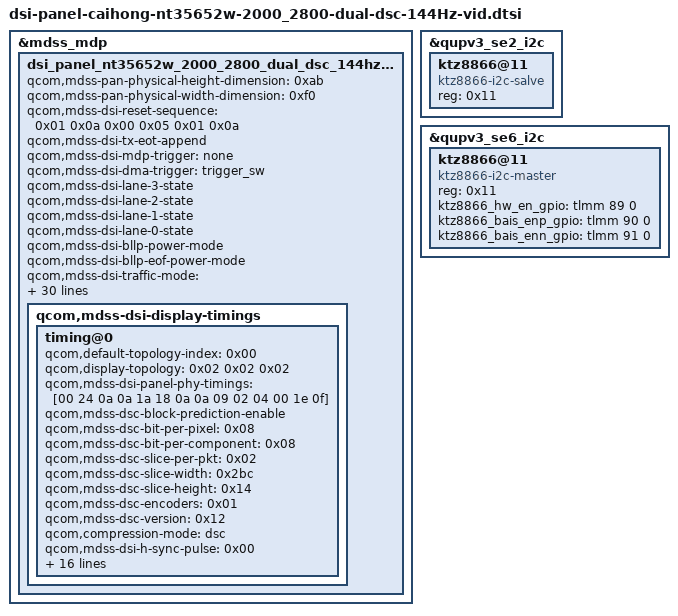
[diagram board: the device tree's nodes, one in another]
&mdss_mdp {
	dsi_panel_nt35652w_2000_2800_dual_dsc_144hz_vid: qcom,mdss_dsi_panel_nt35652w_2000_2800_dual_dsc_144hz_vid {
		qcom,mdss-pan-physical-height-dimension = <0xab>;
		qcom,mdss-pan-physical-width-dimension = <0xf0>;
		qcom,mdss-dsi-reset-sequence = <0x01 0x0a 0x00 0x05 0x01 0x0a>;
		qcom,mdss-dsi-tx-eot-append;
		qcom,mdss-dsi-mdp-trigger = "none";
		qcom,mdss-dsi-dma-trigger = "trigger_sw";
		qcom,mdss-dsi-lane-3-state;
		qcom,mdss-dsi-lane-2-state;
		qcom,mdss-dsi-lane-1-state;
		qcom,mdss-dsi-lane-0-state;
		qcom,mdss-dsi-bllp-power-mode;
		qcom,mdss-dsi-bllp-eof-power-mode;
		qcom,mdss-dsi-traffic-mode = "non_burst_sync_event";
		qcom,mdss-dsi-border-color = <0x00>;
		qcom,mdss-dsi-bpp = <0x18>;
		qcom,mdss-dsi-stream = <0x00>;
		qcom,mdss-dsi-virtual-channel-id = <0x00>;
		oplus,mdss-dsi-manufacture = "novatek";
		oplus,mdss-dsi-vendor-name = "NT36523W";
		qcom,mdss-dsi-panel-type = "dsi_video_mode";
		qcom,mdss-dsi-panel-name = "Dual dsi nt36523w video mode panel with DSC";
	};
};

&dsi_panel_nt35652w_2000_2800_dual_dsc_144hz_vid {
	qcom,panel-supply-entries = <&oplus_dsi_panel_custom_pwr_supply>;
	qcom,dsi-ctrl-num = <0 1>;
	qcom,dsi-phy-num = <0 1>;
	qcom,dsi-select-clocks = "pll_byte_clk0", "pll_dsi_clk0";
	qcom,mdss-dsi-bl-pmic-control-type = "bl_ctrl_external";
	qcom,mdss-dsi-bl-min-level = <10>;
	qcom,mdss-dsi-bl-max-level = <2047>;
	qcom,mdss-brightness-max-level = <2047>;
	qcom,mdss-dsi-bl-inverted-dbv;
	qcom,platform-reset-gpio = <&tlmm 133 0>;
	qcom,esd-check-enabled;
	qcom,mdss-dsi-panel-status-check-mode = "error_flag";
	qcom,error-flag-gpio = <&tlmm 86 0>;
	qcom,error-flag-gpio-slave = <&tlmm 43 0>;
	oplus,bl-use-ktz8866-ic-ctrl;
	oplus,dp-enabled;

	qcom,mdss-dsi-display-timings {
		timing@0 {
			qcom,default-topology-index = <0x00>;
			qcom,display-topology = <0x02 0x02 0x02>;
			qcom,mdss-dsi-panel-phy-timings = [00 24 0a 0a 1a 18 0a 0a 09 02 04 00 1e 0f];
			qcom,mdss-dsc-block-prediction-enable;
			qcom,mdss-dsc-bit-per-pixel = <0x08>;
			qcom,mdss-dsc-bit-per-component = <0x08>;
			qcom,mdss-dsc-slice-per-pkt = <0x02>;
			qcom,mdss-dsc-slice-width = <0x2bc>;
			qcom,mdss-dsc-slice-height = <0x14>;
			qcom,mdss-dsc-encoders = <0x01>;
			qcom,mdss-dsc-version = <0x12>;
			qcom,compression-mode = "dsc";
			qcom,mdss-dsi-h-sync-pulse = <0x00>;
			qcom,mdss-dsi-off-command-state = "dsi_lp_mode";
			qcom,mdss-dsi-on-command-state = "dsi_lp_mode";
			qcom,mdss-dsi-off-command = [05 01 00 00 0a 00 02 28 00 05 01 00 00 41 00 02 10 00];
			qcom,mdss-dsi-on-command = [15 01 00 00 00 00 02 ff 20 15 01 00 00 00 00 02 fb 01 15 01 00 00 00 00 02 62 36 15 01 00 00 00 00 02 63 a4 15 01 00 00 00 00 02 7c 22 15 01 00 00 00 00 02 ff 23 15 01 00 00 00 00 02 fb 01 15 01 00 00 00 00 02 00 60 15 01 00 00 00 00 02 07 20 15 01 00 00 00 00 02 08 01 15 01 00 00 00 00 02 09 5a 15 01 00 00 00 00 02 10 0c 15 01 00 00 00 00 02 11 03 15 01 00 00 00 00 02 12 6b 15 01 00 00 00 00 02 15 03 15 01 00 00 00 00 02 16 10 15 01 00 00 00 00 02 0a 8e 15 01 00 00 00 00 02 0b 8e 15 01 00 00 00 00 02 0c 8e 15 01 00 00 00 00 02 0d 00 15 01 00 00 00 00 02 19 00 15 01 00 00 00 00 02 1a 04 15 01 00 00 00 00 02 1b 08 15 01 00 00 00 00 02 1c 0c 15 01 00 00 00 00 02 1d 10 15 01 00 00 00 00 02 1e 14 15 01 00 00 00 00 02 1f 18 15 01 00 00 00 00 02 20 1c 15 01 00 00 00 00 02 21 20 15 01 00 00 00 00 02 22 24 15 01 00 00 00 00 02 23 28 15 01 00 00 00 00 02 24 2c 15 01 00 00 00 00 02 25 30 15 01 00 00 00 00 02 26 34 15 01 00 00 00 00 02 27 38 15 01 00 00 00 00 02 28 3c 15 01 00 00 00 00 02 2a 20 15 01 00 00 00 00 02 2b 20 15 01 00 00 00 00 02 30 ff 15 01 00 00 00 00 02 31 fd 15 01 00 00 00 00 02 32 fc 15 01 00 00 00 00 02 33 fa 15 01 00 00 00 00 02 34 f8 15 01 00 00 00 00 02 35 f6 15 01 00 00 00 00 02 36 f4 15 01 00 00 00 00 02 37 f2 15 01 00 00 00 00 02 38 f0 15 01 00 00 00 00 02 39 ee 15 01 00 00 00 00 02 3a ec 15 01 00 00 00 00 02 3b ea 15 01 00 00 00 00 02 3d e9 15 01 00 00 00 00 02 3f e8 15 01 00 00 00 00 02 40 e7 15 01 00 00 00 00 02 41 e6 15 01 00 00 00 00 02 45 ff 15 01 00 00 00 00 02 46 f9 15 01 00 00 00 00 02 47 f6 15 01 00 00 00 00 02 48 f2 15 01 00 00 00 00 02 49 f0 15 01 00 00 00 00 02 4a ec 15 01 00 00 00 00 02 4b e8 15 01 00 00 00 00 02 4c e4 15 01 00 00 00 00 02 4d e0 15 01 00 00 00 00 02 4e de 15 01 00 00 00 00 02 4f d9 15 01 00 00 00 00 02 50 d6 15 01 00 00 00 00 02 51 d4 15 01 00 00 00 00 02 52 c2 15 01 00 00 00 00 02 53 d0 15 01 00 00 00 00 02 54 cd 15 01 00 00 00 00 02 58 ff 15 01 00 00 00 00 02 59 f6 15 01 00 00 00 00 02 5a f0 15 01 00 00 00 00 02 5b eb 15 01 00 00 00 00 02 5c e8 15 01 00 00 00 00 02 5d e5 15 01 00 00 00 00 02 5e e3 15 01 00 00 00 00 02 5f e0 15 01 00 00 00 00 02 60 de 15 01 00 00 00 00 02 61 da 15 01 00 00 00 00 02 62 d7 15 01 00 00 00 00 02 63 d4 15 01 00 00 00 00 02 64 d2 15 01 00 00 00 00 02 65 d0 15 01 00 00 00 00 02 66 cc 15 01 00 00 00 00 02 67 c8 15 01 00 00 00 00 02 ff 24 15 01 00 00 00 00 02 fb 01 15 01 00 00 00 00 02 1c 80 15 01 00 00 00 00 02 3a 58 15 01 00 00 00 00 02 3b 58 15 01 00 00 00 00 02 5a 02 15 01 00 00 00 00 02 5b 52 39 01 00 00 00 00 03 5e 00 04 39 01 00 00 00 00 04 92 64 01 0d 15 01 00 00 00 00 02 98 80 15 01 00 00 00 00 02 db 73 15 01 00 00 00 00 02 de 08 15 01 00 00 00 00 02 ff 25 15 01 00 00 00 00 02 fb 01 15 01 00 00 00 00 02 05 00 15 01 00 00 00 00 02 1f 02 15 01 00 00 00 00 02 20 52 15 01 00 00 00 00 02 23 09 15 01 00 00 00 00 02 24 1d 15 01 00 00 00 00 02 26 02 15 01 00 00 00 00 02 27 52 15 01 00 00 00 00 02 2a 09 15 01 00 00 00 00 02 2b 1d 15 01 00 00 00 00 02 31 20 15 01 00 00 00 00 02 3a 01 15 01 00 00 00 00 02 42 0b 15 01 00 00 00 00 02 68 04 15 01 00 00 00 00 02 6a 00 15 01 00 00 00 00 02 c0 0c 15 01 00 00 00 00 02 c2 a5 15 01 00 00 00 00 02 ff 26 15 01 00 00 00 00 02 fb 01 15 01 00 00 00 00 02 04 74 39 01 00 00 00 00 05 19 1f 1e 1f 1f 39 01 00 00 00 00 05 1a e5 c1 e5 e5 39 01 00 00 00 00 05 1b 1f 1d 1f 1f 39 01 00 00 00 00 05 1c 04 e1 04 04 15 01 00 00 00 00 02 1e 64 15 01 00 00 00 00 02 1f 64 39 01 00 00 00 00 05 2a 1f 1e 1f 1f 39 01 00 00 00 00 05 2b dc b9 dc dc 15 01 00 00 00 00 02 2f 0b 15 01 00 00 00 00 02 30 64 15 01 00 00 00 00 02 32 64 15 01 00 00 00 00 02 33 22 15 01 00 00 00 00 02 34 92 15 01 00 00 00 00 02 35 78 15 01 00 00 00 00 02 36 96 15 01 00 00 00 00 02 37 78 15 01 00 00 00 00 02 38 06 15 01 00 00 00 00 02 3a 64 39 01 00 00 00 00 04 3d 00 a0 2a 15 01 00 00 00 00 02 40 64 15 01 00 00 00 00 02 41 64 15 01 00 00 00 00 02 42 64 15 01 00 00 00 00 02 45 0b 15 01 00 00 00 00 02 46 64 15 01 00 00 00 00 02 48 64 15 01 00 00 00 00 02 4a 64 15 01 00 00 00 00 02 4d 58 15 01 00 00 00 00 02 4e 58 15 01 00 00 00 00 02 51 02 15 01 00 00 00 00 02 52 52 15 01 00 00 00 00 02 56 02 15 01 00 00 00 00 02 58 52 15 01 00 00 00 00 02 5b 02 15 01 00 00 00 00 02 5c 52 39 01 00 00 00 00 04 84 1d 1d 1d 39 01 00 00 00 00 05 99 23 23 23 23 39 01 00 00 00 00 05 9a 97 97 97 97 39 01 00 00 00 00 05 9b 22 22 22 22 39 01 00 00 00 00 05 9c b5 b5 b5 b5 39 01 00 00 00 00 05 9d 23 23 23 23 39 01 00 00 00 00 05 9e 8d 8d 8d 8d 15 01 00 00 00 00 02 a7 08 15 01 00 00 00 00 02 ff 27 15 01 00 00 00 00 02 fb 01 15 01 00 00 00 00 02 30 f0 15 01 00 00 00 00 02 31 2a 15 01 00 00 00 00 02 76 f0 15 01 00 00 00 00 02 77 02 15 01 00 00 00 00 02 79 13 39 01 00 00 00 00 03 80 c0 08 39 01 00 00 00 00 03 81 2d 00 39 01 00 00 00 00 03 82 a5 80 39 01 00 00 00 00 03 84 5f 00 39 01 00 00 00 00 03 85 28 00 39 01 00 00 00 00 03 86 a5 80 39 01 00 00 00 00 03 88 5f 00 15 01 00 00 00 00 02 96 f0 15 01 00 00 00 00 02 97 2a 15 01 00 00 00 00 02 ff 2a 15 01 00 00 00 00 02 fb 01 15 01 00 00 00 00 02 14 09 15 01 00 00 00 00 02 1e 09 15 01 00 00 00 00 02 1f 09 15 01 00 00 00 00 02 64 36 15 01 00 00 00 00 02 67 3e 15 01 00 00 00 00 02 6a 36 15 01 00 00 00 00 02 6d 36 15 01 00 00 00 00 02 70 36 15 01 00 00 00 00 02 73 36 15 01 00 00 00 00 02 76 36 15 01 00 00 00 00 02 79 3e 15 01 00 00 00 00 02 7c 36 15 01 00 00 00 00 02 7f 36 15 01 00 00 00 00 02 82 36 15 01 00 00 00 00 02 85 3e 15 01 00 00 00 00 02 88 3e 15 01 00 00 00 00 02 8b 36 15 01 00 00 00 00 02 8e 36 15 01 00 00 00 00 02 91 36 15 01 00 00 00 00 02 94 36 39 01 00 00 00 00 04 9f 36 00 00 39 01 00 00 00 00 04 a0 36 00 00 15 01 00 00 00 00 02 a3 00 39 01 00 00 00 00 04 b3 36 00 00 15 01 00 00 00 00 02 c4 02 15 01 00 00 00 00 02 c5 09 15 01 00 00 00 00 02 c6 1d 15 01 00 00 00 00 02 c8 0b 39 01 00 00 00 00 07 cc a5 5a 00 55 00 00 15 01 00 00 00 00 02 d0 84 15 01 00 00 00 00 02 ff 10 15 01 00 00 00 00 02 fb 01 39 01 00 00 00 00 03 51 07 ff 15 01 00 00 00 00 02 53 2c 15 01 00 00 00 00 02 b9 00 15 01 00 00 00 00 02 55 00 15 01 00 00 00 00 02 b9 02 39 01 00 00 00 00 07 3b 03 c6 1a 0a 0a 00 15 01 00 00 00 00 02 90 03 39 01 00 00 00 00 11 91 89 a8 00 14 d2 00 02 7d 02 0e 00 09 05 7a 03 dc 39 01 00 00 00 00 03 92 10 d0 15 01 00 00 00 00 02 9d 01 15 01 00 00 00 00 02 b2 91 15 01 00 00 00 00 02 b3 40 15 01 00 00 00 00 02 ff 10 15 01 00 00 00 00 02 fb 01 05 01 00 00 78 00 02 11 00 05 01 00 00 0a 00 02 29 00];
			qcom,mdss-dsi-panel-framerate = <0x78>;
			qcom,mdss-dsi-v-pulse-width = <0x02>;
			qcom,mdss-dsi-v-front-porch = <0x1a>;
			qcom,mdss-dsi-v-back-porch = <0xc4>;
			qcom,mdss-dsi-h-sync-skew = <0x00>;
			qcom,mdss-dsi-h-pulse-width = <0x1c>;
			qcom,mdss-dsi-h-back-porch = <0x1a>;
			qcom,mdss-dsi-h-front-porch = <0xaa>;
			qcom,mdss-dsi-panel-height = <0x7d0>;
			qcom,mdss-dsi-panel-width = <0x578>;
		};
	};
};

&qupv3_se2_i2c {
	status = "ok";
	ktz8866@11 {
		compatible = "ktz8866-i2c-salve";
		reg = <0x11>;
	};
};

&qupv3_se6_i2c {
	status = "ok";
	ktz8866@11 {
		compatible = "ktz8866-i2c-master";
		reg = <0x11>;
		ktz8866_hw_en_gpio = <&tlmm 89 0>;
		ktz8866_bais_enp_gpio = <&tlmm 90 0>;
		ktz8866_bais_enn_gpio = <&tlmm 91 0>;
	};
};
